# LargeDummyDevice register map
File version: 1.0
Registers are 32-bit, read-write, no defined reset value unless marked. A register's access mark holds for its fields unless they carry their own. Offsets are from the block's base; [hi:lo] are bit positions.

## PERIPHERAL_78
Base 0x4004D000
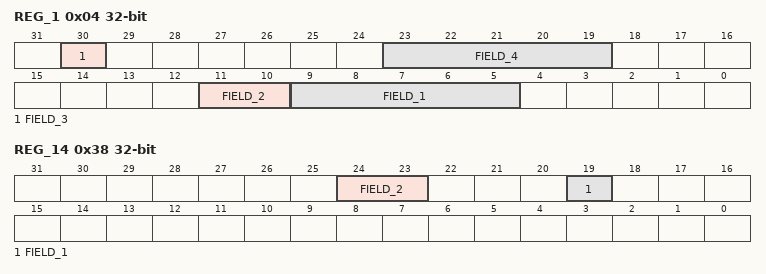
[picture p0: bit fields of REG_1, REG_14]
0x04 REG_1 — Register 1
  [30] FIELD_3, [23:19] FIELD_4, [11:10] FIELD_2, [9:5] FIELD_1
0x08 REG_2 — Register 2
  [32:31] FIELD_16, [31:30] FIELD_22, [28] FIELD_18, [28:27] FIELD_26, [26:25] FIELD_1, [28:25] FIELD_23, [29:25] FIELD_24, [27:23] FIELD_8, [25:22] FIELD_28, [24:21] FIELD_10, [20:19] FIELD_20, [19:18] FIELD_29, [16:14] FIELD_14, [13] FIELD_21, [14:12] FIELD_6, [15:11] FIELD_17, [13:10] FIELD_3, [13:10] FIELD_12, [12:9] FIELD_4, [10:7] FIELD_2, [8:6] FIELD_25, [5] FIELD_9, [7:5] FIELD_15, [5] FIELD_30, [8:4] FIELD_7, [6:3] FIELD_19, [6:3] FIELD_27, [2] FIELD_5, [2:1] FIELD_11, [4:0] FIELD_13
0x0C REG_3 — Register 3
  [33:31] FIELD_16, [32:31] FIELD_29, [30] FIELD_6, [31:30] FIELD_15, [31:30] FIELD_31, [28] FIELD_14, [29:27] FIELD_11, [29:27] FIELD_19, [27:25] FIELD_28, [25:24] FIELD_1, [23] FIELD_8, [24:23] FIELD_20, [27:23] FIELD_22, [26:23] FIELD_26, [23:20] FIELD_18, [22:19] FIELD_4, [19:18] FIELD_3, [18:14] FIELD_17, [17:13] FIELD_9, [16:13] FIELD_13, [14:13] FIELD_21, [13:12] FIELD_7, [14:12] FIELD_30, [15:11] FIELD_2, [13:11] FIELD_24, [10:8] FIELD_23, [8:7] FIELD_25, [10:6] FIELD_5, [4:3] FIELD_10, [7:3] FIELD_27, [5:1] FIELD_12
0x10 REG_4 — Register 4
  [27] FIELD_13, [24:23] FIELD_15, [22:18] FIELD_1, [18:17] FIELD_7, [20:16] FIELD_8, [15] FIELD_14, [17:13] FIELD_10, [14:12] FIELD_12, [14:11] FIELD_6, [10:7] FIELD_11, [7:6] FIELD_3, [6:5] FIELD_2, [9:5] FIELD_9, [5:2] FIELD_5, [2:1] FIELD_4
0x14 REG_5 — Register 5
  [30] FIELD_31, [31:28] FIELD_10, [28:27] FIELD_1, [28:27] FIELD_20, [26:25] FIELD_22, [28:24] FIELD_15, [24:23] FIELD_6, [25:22] FIELD_4, [26:22] FIELD_18, [25:22] FIELD_25, [25:21] FIELD_7, [25:21] FIELD_11, [24:21] FIELD_24, [24:21] FIELD_27, [21:20] FIELD_8, [24:20] FIELD_21, [19:18] FIELD_12, [19:18] FIELD_26, [19:15] FIELD_9, [15:14] FIELD_30, [14:11] FIELD_29, [9:7] FIELD_2, [7] FIELD_17, [8:6] FIELD_5, [6] FIELD_19, [7:5] FIELD_13, [7:4] FIELD_3, [3:2] FIELD_23, [3:1] FIELD_14, [1:0] FIELD_16, [2:0] FIELD_28
0x18 REG_6 — Register 6
  [28] FIELD_1, [27] FIELD_11, [25] FIELD_2, [26:25] FIELD_10, [25:24] FIELD_18, [24:22] FIELD_6, [22:20] FIELD_14, [19:18] FIELD_15, [20:17] FIELD_21, [19:16] FIELD_3, [19:16] FIELD_8, [19:15] FIELD_19, [16:12] FIELD_12, [15:12] FIELD_13, [15:11] FIELD_5, [12:9] FIELD_20, [12:8] FIELD_22, [9:6] FIELD_16, [4:2] FIELD_4, [5:1] FIELD_9, [2:0] FIELD_7, [3:0] FIELD_17
0x1C REG_7 — Register 7
  [31:29] FIELD_2, [31:27] FIELD_5, [25:24] FIELD_6, [23:21] FIELD_1, [18:17] FIELD_3, [8:5] FIELD_4
0x20 REG_8 — Register 8
  [34:31] FIELD_9, [28] FIELD_8, [30:27] FIELD_2, [26:22] FIELD_7, [24:21] FIELD_11, [22:21] FIELD_15, [16] FIELD_10, [18:16] FIELD_16, [15] FIELD_17, [15:13] FIELD_5, [12] FIELD_1, [16:12] FIELD_4, [14:12] FIELD_6, [12:10] FIELD_12, [12:9] FIELD_3, [10:9] FIELD_13, [6:5] FIELD_14
0x24 REG_9 — Register 9
  [33:30] FIELD_8, [28:27] FIELD_13, [28:27] FIELD_14, [29:25] FIELD_15, [28:24] FIELD_9, [23] FIELD_6, [23] FIELD_18, [24:22] FIELD_22, [22:20] FIELD_20, [20:19] FIELD_11, [20:19] FIELD_12, [21:18] FIELD_4, [15:12] FIELD_7, [13:9] FIELD_10, [7] FIELD_3, [10:7] FIELD_19, [6] FIELD_16, [8:5] FIELD_23, [2] FIELD_1, [6:2] FIELD_5, [4:1] FIELD_17, [3:0] FIELD_2, [2:0] FIELD_21
0x28 REG_10 — Register 10
  [32:31] FIELD_3, [23] FIELD_2, [21] FIELD_1, [19:17] FIELD_4, [14:10] FIELD_5
0x2C REG_11 — Register 11
  [18:16] FIELD_1
0x30 REG_12 — Register 12
  [35:31] FIELD_22, [29] FIELD_1, [29] FIELD_6, [28:26] FIELD_9, [28:24] FIELD_2, [28:24] FIELD_11, [26:24] FIELD_19, [25:23] FIELD_4, [25:22] FIELD_3, [21:20] FIELD_13, [20:16] FIELD_18, [15:14] FIELD_5, [16:13] FIELD_23, [12] FIELD_15, [11:7] FIELD_8, [7] FIELD_14, [11:7] FIELD_21, [7:5] FIELD_7, [7:5] FIELD_20, [7:3] FIELD_10, [4:2] FIELD_17, [5:1] FIELD_12, [4:1] FIELD_16
0x34 REG_13 — Register 13
  [35:31] FIELD_8, [31] FIELD_14, [31:29] FIELD_10, [29:26] FIELD_1, [26] FIELD_13, [24:21] FIELD_2, [20:17] FIELD_6, [21:17] FIELD_9, [14] FIELD_4, [14:13] FIELD_12, [14:11] FIELD_11, [12:9] FIELD_3, [8:5] FIELD_5, [6:5] FIELD_7
0x38 REG_14 — Register 14
  [24:23] FIELD_2, [19] FIELD_1
0x3C REG_15 — Register 15
  [33:29] FIELD_7, [32:28] FIELD_10, [29:25] FIELD_3, [25:23] FIELD_4, [27:23] FIELD_9, [22] FIELD_5, [21:20] FIELD_2, [22:20] FIELD_17, [21:18] FIELD_1, [21:18] FIELD_13, [18:17] FIELD_14, [16:13] FIELD_11, [12] FIELD_6, [15:12] FIELD_16, [6:3] FIELD_12, [4:3] FIELD_18, [5:2] FIELD_8, [1] FIELD_15
0x40 REG_16 — Register 16
  [20:18] FIELD_1, [11:8] FIELD_4, [10:7] FIELD_2, [0] FIELD_3
0x44 REG_17 — Register 17
  [29] FIELD_7, [27:25] FIELD_4, [27:24] FIELD_3, [27:23] FIELD_2, [22:19] FIELD_5, [15] FIELD_8, [12] FIELD_1, [14:11] FIELD_10, [8:7] FIELD_11, [5:4] FIELD_6, [2] FIELD_9
0x48 REG_18 — Register 18
  [31:30] FIELD_14, [32:30] FIELD_21, [30:29] FIELD_8, [30:29] FIELD_23, [28:25] FIELD_15, [28:24] FIELD_11, [27:23] FIELD_7, [26:23] FIELD_16, [24:23] FIELD_17, [25:22] FIELD_6, [20:19] FIELD_3, [20:17] FIELD_12, [17] FIELD_22, [18:16] FIELD_20, [16:13] FIELD_2, [13:12] FIELD_18, [16:12] FIELD_25, [11:9] FIELD_10, [5] FIELD_13, [6:3] FIELD_19, [6:2] FIELD_1, [3:2] FIELD_5, [6:2] FIELD_9, [4:2] FIELD_24, [0] FIELD_4
0x4C REG_19 — Register 19
  [32:30] FIELD_2, [32:30] FIELD_6, [23:20] FIELD_1, [16:12] FIELD_3, [11] FIELD_4, [7:4] FIELD_5
0x50 REG_20 — Register 20
  [28:27] FIELD_1, [31:27] FIELD_10, [30:26] FIELD_7, [26:25] FIELD_6, [27:23] FIELD_2, [15:12] FIELD_3, [9] FIELD_5, [10:8] FIELD_4, [9:6] FIELD_9, [2:0] FIELD_8
0x54 REG_21 — Register 21
  [17:16] FIELD_1
0x58 REG_22 — Register 22
  [32:31] FIELD_12, [23] FIELD_10, [23:20] FIELD_2, [17] FIELD_3, [16] FIELD_11, [16:15] FIELD_1, [18:14] FIELD_5, [12:8] FIELD_7, [9:7] FIELD_9, [7:4] FIELD_4, [4:3] FIELD_8, [1:0] FIELD_6
0x5C REG_23 — Register 23
  [31:27] FIELD_10, [23] FIELD_15, [22] FIELD_7, [19:17] FIELD_3, [16] FIELD_5, [15:12] FIELD_14, [14:11] FIELD_9, [14:11] FIELD_11, [10:8] FIELD_1, [10:8] FIELD_4, [6] FIELD_2, [6] FIELD_6, [10:6] FIELD_12, [5:1] FIELD_8, [1] FIELD_13
0x60 REG_24 — Register 24
  [31] FIELD_1, [26] FIELD_4, [25:22] FIELD_7, [18:17] FIELD_11, [17:16] FIELD_9, [15:13] FIELD_6, [12] FIELD_10, [7] FIELD_5, [11:7] FIELD_8, [7:5] FIELD_3, [4:3] FIELD_2
0x64 REG_25 — Register 25
  [31:30] FIELD_10, [30:29] FIELD_5, [30:28] FIELD_4, [27] FIELD_9, [28:27] FIELD_20, [27] FIELD_22, [30:26] FIELD_23, [26] FIELD_26, [26:24] FIELD_8, [25:21] FIELD_1, [21:20] FIELD_7, [21:19] FIELD_17, [19:17] FIELD_24, [17:16] FIELD_2, [17:15] FIELD_3, [16:15] FIELD_21, [18:14] FIELD_6, [17:14] FIELD_13, [10] FIELD_12, [5:4] FIELD_19, [4:3] FIELD_15, [5:3] FIELD_25, [2] FIELD_14, [5:2] FIELD_16, [6:2] FIELD_18, [3:0] FIELD_11
0x68 REG_26 — Register 26
  [34:31] FIELD_6, [30:26] FIELD_1, [26] FIELD_10, [28:25] FIELD_12, [19:18] FIELD_8, [21:18] FIELD_11, [19:17] FIELD_2, [15] FIELD_4, [13] FIELD_3, [14:11] FIELD_5, [9:7] FIELD_9, [1] FIELD_7
0x6C REG_27 — Register 27
  [33:29] FIELD_7, [29:25] FIELD_10, [25] FIELD_13, [22:20] FIELD_8, [24:20] FIELD_17, [20:19] FIELD_3, [21:18] FIELD_1, [16:15] FIELD_11, [18:15] FIELD_15, [14:13] FIELD_16, [12] FIELD_2, [13:12] FIELD_19, [15:11] FIELD_5, [13:11] FIELD_9, [11:9] FIELD_18, [8:6] FIELD_14, [7:5] FIELD_4, [3] FIELD_12, [3:2] FIELD_6
0x70 REG_28 — Register 28
  [33:30] FIELD_6, [33:30] FIELD_23, [30:29] FIELD_3, [26:24] FIELD_17, [25:21] FIELD_10, [25:21] FIELD_15, [23:20] FIELD_18, [19] FIELD_11, [19:17] FIELD_19, [19:16] FIELD_22, [15:14] FIELD_5, [16:13] FIELD_1, [15:13] FIELD_12, [14:12] FIELD_4, [11:10] FIELD_13, [12:9] FIELD_14, [9] FIELD_21, [9:7] FIELD_7, [10:7] FIELD_9, [10:6] FIELD_8, [6] FIELD_16, [7:3] FIELD_2, [4:0] FIELD_20
0x74 REG_29 — Register 29
  [31] FIELD_7, [32:31] FIELD_16, [32:31] FIELD_20, [30] FIELD_11, [32:28] FIELD_14, [27] FIELD_24, [25:24] FIELD_23, [25:23] FIELD_6, [23:22] FIELD_1, [24:22] FIELD_3, [22:21] FIELD_4, [25:21] FIELD_8, [20:17] FIELD_12, [18:14] FIELD_5, [15:12] FIELD_13, [7:6] FIELD_2, [6:5] FIELD_19, [7:5] FIELD_22, [8:5] FIELD_25, [5:3] FIELD_18, [2] FIELD_10, [5:1] FIELD_15, [0] FIELD_9, [1:0] FIELD_17, [0] FIELD_21
0x78 REG_30 — Register 30
  [25] FIELD_7, [23] FIELD_4, [22] FIELD_6, [21:19] FIELD_3, [23:19] FIELD_9, [13:10] FIELD_2, [12:8] FIELD_1, [9:6] FIELD_10, [7:5] FIELD_8, [3] FIELD_5
0x7C REG_31 — Register 31
  [31:30] FIELD_27, [33:29] FIELD_5, [29:27] FIELD_1, [29:27] FIELD_17, [24:23] FIELD_13, [25:22] FIELD_7, [23:20] FIELD_6, [20] FIELD_25, [20:19] FIELD_21, [20:19] FIELD_24, [21:18] FIELD_8, [22:18] FIELD_22, [20:18] FIELD_26, [21:17] FIELD_16, [17:15] FIELD_15, [18:15] FIELD_20, [15:14] FIELD_23, [13] FIELD_29, [15:12] FIELD_11, [12:11] FIELD_10, [11:9] FIELD_19, [9:7] FIELD_3, [8:7] FIELD_4, [8:7] FIELD_9, [8:6] FIELD_2, [7:6] FIELD_14, [8:5] FIELD_12, [6:5] FIELD_28, [3:0] FIELD_18
0x80 REG_32 — Register 32
  [33:30] FIELD_16, [31:30] FIELD_20, [30:29] FIELD_3, [30:29] FIELD_11, [32:28] FIELD_7, [26:25] FIELD_8, [27:23] FIELD_4, [26:23] FIELD_10, [21:20] FIELD_18, [20:16] FIELD_21, [20:16] FIELD_23, [15] FIELD_6, [17:15] FIELD_17, [14:13] FIELD_19, [14:11] FIELD_5, [13:10] FIELD_22, [9:7] FIELD_2, [7:6] FIELD_12, [7:3] FIELD_1, [6:2] FIELD_15, [3:0] FIELD_9, [1:0] FIELD_13, [0] FIELD_14
0x84 REG_33 — Register 33
  [33:29] FIELD_24, [32:28] FIELD_12, [29:28] FIELD_15, [31:28] FIELD_17, [27] FIELD_18, [28:26] FIELD_9, [26] FIELD_26, [28:25] FIELD_2, [27:24] FIELD_21, [20:17] FIELD_8, [17] FIELD_11, [19:16] FIELD_4, [17:15] FIELD_13, [17:15] FIELD_23, [13] FIELD_1, [13] FIELD_10, [13] FIELD_20, [14:11] FIELD_14, [15:11] FIELD_25, [10:9] FIELD_5, [9] FIELD_6, [11:7] FIELD_3, [5] FIELD_22, [5:4] FIELD_7, [7:4] FIELD_16, [4:0] FIELD_19
0x88 REG_34 — Register 34
  [31:30] FIELD_21, [33:30] FIELD_22, [28:27] FIELD_3, [28:27] FIELD_9, [27:26] FIELD_18, [23:22] FIELD_1, [24:22] FIELD_6, [24:22] FIELD_7, [21] FIELD_15, [25:21] FIELD_19, [19] FIELD_2, [22:18] FIELD_25, [17] FIELD_13, [19:16] FIELD_20, [16:12] FIELD_4, [16:12] FIELD_14, [15:12] FIELD_24, [9] FIELD_8, [9:6] FIELD_12, [6:3] FIELD_10, [6:3] FIELD_11, [3:2] FIELD_16, [2] FIELD_17, [5:1] FIELD_23, [1:0] FIELD_5, [1:0] FIELD_26
0x8C REG_35 — Register 35
  [32:30] FIELD_6, [30] FIELD_11, [30:29] FIELD_23, [31:28] FIELD_15, [31:27] FIELD_12, [29:26] FIELD_17, [26:24] FIELD_1, [24:22] FIELD_20, [20:19] FIELD_4, [20:19] FIELD_18, [21:18] FIELD_13, [15:14] FIELD_14, [13:12] FIELD_19, [14:11] FIELD_22, [13:10] FIELD_5, [12:10] FIELD_7, [9:7] FIELD_9, [8:7] FIELD_10, [7:4] FIELD_2, [7:4] FIELD_8, [6:2] FIELD_21, [3:1] FIELD_3, [5:1] FIELD_16
0x90 REG_36 — Register 36
  [32:30] FIELD_4, [29:27] FIELD_5, [28:26] FIELD_2, [27:26] FIELD_14, [24] FIELD_3, [23] FIELD_13, [25:21] FIELD_10, [22:21] FIELD_18, [22:21] FIELD_21, [22:20] FIELD_7, [20:18] FIELD_6, [17] FIELD_1, [17] FIELD_17, [18:15] FIELD_15, [16:12] FIELD_8, [11] FIELD_20, [9] FIELD_11, [9:8] FIELD_9, [11:7] FIELD_19, [9:6] FIELD_12, [2] FIELD_16
0x94 REG_37 — Register 37
  [31] FIELD_10, [31:29] FIELD_19, [28] FIELD_17, [31:27] FIELD_20, [30:26] FIELD_2, [28:25] FIELD_27, [27:24] FIELD_22, [26:23] FIELD_4, [27:23] FIELD_24, [22:21] FIELD_9, [21:20] FIELD_23, [19] FIELD_13, [19] FIELD_26, [18:17] FIELD_3, [19:15] FIELD_16, [18:14] FIELD_11, [12] FIELD_5, [15:12] FIELD_18, [11:8] FIELD_15, [8:7] FIELD_6, [6] FIELD_14, [6] FIELD_25, [8:5] FIELD_8, [6:4] FIELD_7, [4:3] FIELD_1, [4:2] FIELD_12, [5:1] FIELD_21
0x98 REG_38 — Register 38
  [32:30] FIELD_6, [26] FIELD_8, [23:20] FIELD_1, [18] FIELD_10, [18:15] FIELD_2, [17:15] FIELD_3, [13:12] FIELD_9, [15:11] FIELD_11, [10:9] FIELD_7, [9:7] FIELD_4, [7:5] FIELD_5, [3] FIELD_12
0x9C REG_39 — Register 39
  [33:31] FIELD_3, [31:29] FIELD_6, [31:28] FIELD_1, [31:27] FIELD_4, [29:26] FIELD_9, [22:19] FIELD_2, [16] FIELD_11, [8:5] FIELD_5, [7:3] FIELD_7, [2:0] FIELD_8, [4:0] FIELD_10, [3:0] FIELD_12
0xA0 REG_40 — Register 40
  [35:31] FIELD_13, [31:30] FIELD_14, [30:28] FIELD_7, [29:27] FIELD_9, [27:25] FIELD_2, [28:24] FIELD_3, [27:24] FIELD_12, [27:23] FIELD_5, [24:21] FIELD_10, [23:20] FIELD_11, [20:19] FIELD_1, [21:17] FIELD_17, [16:15] FIELD_4, [15:13] FIELD_16, [12] FIELD_8, [8:5] FIELD_18, [6:4] FIELD_6, [6:4] FIELD_15
0xA4 REG_41 — Register 41
  [27] FIELD_9, [24] FIELD_4, [25:24] FIELD_7, [24:23] FIELD_1, [24:23] FIELD_11, [22:18] FIELD_12, [20:16] FIELD_5, [14:10] FIELD_8, [12:9] FIELD_3, [12:9] FIELD_10, [3:1] FIELD_2, [0] FIELD_6
